VERSION ""

NS_ :

BS_:

BU_: MCU PC
VAL_TABLE_ McuCtrlMode 7 "Failure" 6 "SpdMode" 5 "TrqMode" 4 "HVStandby" 3 "LVStandby" 2 "Calib" 1 "Init" 0 "Sleep" ;

BO_ 3221225472 VECTOR__INDEPENDENT_SIG_MSG: 0 Vector__XXX
 SG_ MCU_TrqFbk : 0|8@0- (0.005,0) [-0.64|0.635] "Nm" Vector__XXX
 SG_ MCU_ModIdx : 0|7@0+ (0.01,0) [0|1.27] "" Vector__XXX
 SG_ MCU_SpdFbk : 0|16@0- (1,0) [-32768|32767] "rpm" Vector__XXX

BO_ 513 MCU_201h: 4 MCU
 SG_ MCU_Task10msLoad : 23|16@0+ (0.01,0) [0|10] "ms" Vector__XXX
 SG_ MCU_CpuLoad : 7|16@0+ (1,0) [0|65535] "" Vector__XXX

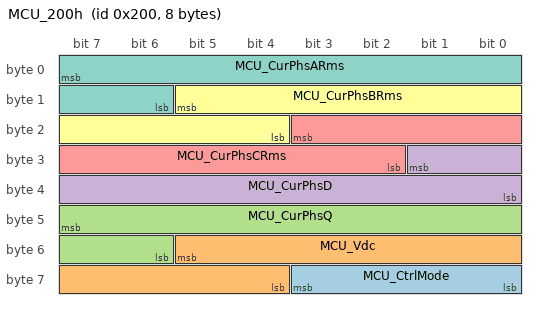
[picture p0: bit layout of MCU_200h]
BO_ 512 MCU_200h: 8 MCU
 SG_ MCU_CtrlMode : 59|4@0+ (1,0) [0|15] ""  PC
 SG_ MCU_Vdc : 53|10@0+ (0.1,0) [0|102.3] "V"  PC
 SG_ MCU_CurPhsQ : 47|10@0- (0.01,0) [-5.12|5.11] "A"  PC
 SG_ MCU_CurPhsD : 25|10@0- (0.01,0) [-5.12|5.11] "A"  PC
 SG_ MCU_CurPhsCRms : 19|10@0- (0.01,0) [-5.12|5.11] "A"  PC
 SG_ MCU_CurPhsBRms : 13|10@0- (0.01,0) [-5.12|5.11] "A"  PC
 SG_ MCU_CurPhsARms : 7|10@0- (0.01,0) [-5.12|5.11] "A"  PC

BO_ 256 PC: 8 Vector__XXX

CM_ BO_ 3221225472 "This is a message for not used signals, created by Vector CANdb++ DBC OLE DB Provider.";
CM_ SG_ 512 MCU_CurPhsCRms "电机 C 相电流有效值";
CM_ SG_ 512 MCU_CurPhsBRms "电机 B 相电流有效值";
CM_ SG_ 512 MCU_CurPhsARms "电机 A 相电流有效值";
BA_DEF_ BO_  "GenMsgCycleTime" INT 0 0;
BA_DEF_ BO_  "GenMsgSendType" ENUM  "Cycle","NoSendType","IfActive";
BA_DEF_  "BusType" STRING ;
BA_DEF_DEF_  "GenMsgCycleTime" 0;
BA_DEF_DEF_  "GenMsgSendType" "Cycle";
BA_DEF_DEF_  "BusType" "CAN";
BA_ "GenMsgCycleTime" BO_ 513 10;
BA_ "GenMsgCycleTime" BO_ 512 10;
VAL_ 512 MCU_CtrlMode 7 "Failure" 6 "SpdMode" 5 "TrqMode" 4 "HVStandby" 3 "LVStandby" 2 "Calib" 1 "Init" 0 "Sleep" ;
